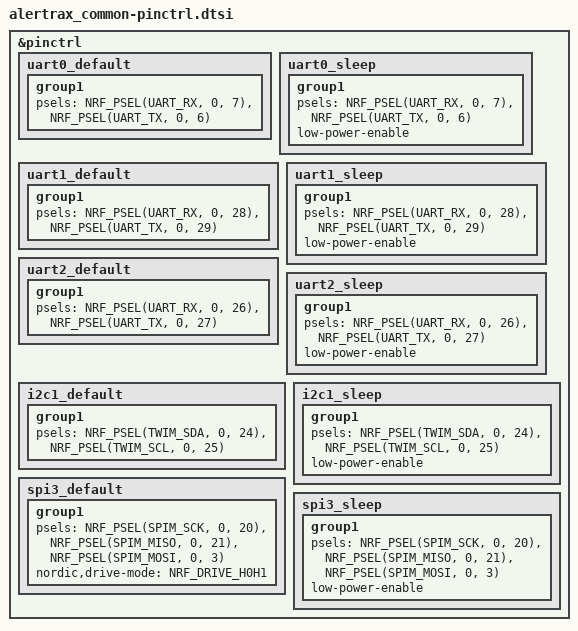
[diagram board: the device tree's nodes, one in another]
/*
 * Copyright (c) 2022 Nordic Semiconductor
 * SPDX-License-Identifier: Apache-2.0
 */

&pinctrl {
	uart0_default: uart0_default {
		group1 {
			psels = <NRF_PSEL(UART_RX, 0, 7)>,
				<NRF_PSEL(UART_TX, 0, 6)>;
		};
	};

	uart0_sleep: uart0_sleep {
		group1 {
			psels = <NRF_PSEL(UART_RX, 0, 7)>,
				<NRF_PSEL(UART_TX, 0, 6)>;
			low-power-enable;
		};
	};

	uart1_default: uart1_default {
		group1 {
			psels = <NRF_PSEL(UART_RX, 0, 28)>,
				<NRF_PSEL(UART_TX, 0, 29)>;
		};
	};

	uart1_sleep: uart1_sleep {
		group1 {
			psels = <NRF_PSEL(UART_RX, 0, 28)>,
				<NRF_PSEL(UART_TX, 0, 29)>;
			low-power-enable;
		};
	};

	uart2_default: uart2_default {
		group1 {
			psels = <NRF_PSEL(UART_RX, 0, 26)>,
				<NRF_PSEL(UART_TX, 0, 27)>;
		};
	};

	uart2_sleep: uart2_sleep {
		group1 {
			psels = <NRF_PSEL(UART_RX, 0, 26)>,
				<NRF_PSEL(UART_TX, 0, 27)>;
			low-power-enable;
		};
	};

	i2c1_default: i2c1_default {
		group1 {
			psels = <NRF_PSEL(TWIM_SDA, 0, 24)>,
				<NRF_PSEL(TWIM_SCL, 0, 25)>;
		};
	};

	i2c1_sleep: i2c1_sleep {
		group1 {
			psels = <NRF_PSEL(TWIM_SDA, 0, 24)>,
				<NRF_PSEL(TWIM_SCL, 0, 25)>;
			low-power-enable;
		};
	};
	spi3_default: spi3_default {
		group1 {
			psels = <NRF_PSEL(SPIM_SCK, 0, 20)>,
				<NRF_PSEL(SPIM_MISO, 0, 21)>,
				<NRF_PSEL(SPIM_MOSI, 0, 3)>;
			nordic,drive-mode = <NRF_DRIVE_H0H1>;
		};
	};

	spi3_sleep: spi3_sleep {
		group1 {
			psels = <NRF_PSEL(SPIM_SCK, 0, 20)>,
				<NRF_PSEL(SPIM_MISO, 0, 21)>,
				<NRF_PSEL(SPIM_MOSI, 0, 3)>;
			low-power-enable;
			/* bias-pull-up; */
		};
	};

};
